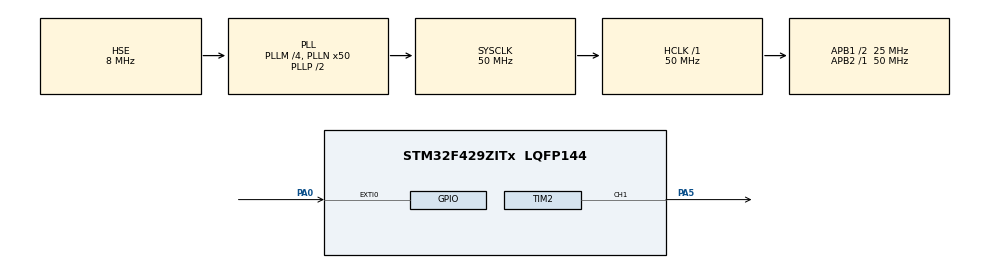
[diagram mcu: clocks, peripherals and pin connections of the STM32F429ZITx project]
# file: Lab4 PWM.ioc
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Mcu.Family=STM32F4
Mcu.Name=STM32F429ZITx
Mcu.Package=LQFP144
NVIC.EXTI0_IRQn=true\:0\:0\:false\:false\:true\:true\:true\:true
NVIC.PriorityGroup=NVIC_PRIORITYGROUP_4
PA0/WKUP.GPIO_ModeDefaultEXTI=GPIO_MODE_IT_RISING
PA0/WKUP.Signal=GPXTI0
PA13.Mode=Serial_Wire
PA13.Signal=SYS_JTMS-SWDIO
PA14.Mode=Serial_Wire
PA14.Signal=SYS_JTCK-SWCLK
PA5.Signal=S_TIM2_CH1_ETR
PH0/OSC_IN.Mode=HSE-External-Oscillator
PH0/OSC_IN.Signal=RCC_OSC_IN
PH1/OSC_OUT.Mode=HSE-External-Oscillator
PH1/OSC_OUT.Signal=RCC_OSC_OUT
ProjectManager.HeapSize=0x200
ProjectManager.StackSize=0x400
ProjectManager.TargetToolchain=STM32CubeIDE
RCC.48MHZClocksFreq_Value=25000000
RCC.AHBFreq_Value=50000000
RCC.APB1CLKDivider=RCC_HCLK_DIV2
RCC.APB1Freq_Value=25000000
RCC.APB1TimFreq_Value=50000000
RCC.APB2Freq_Value=50000000
RCC.APB2TimFreq_Value=50000000
RCC.CortexFreq_Value=50000000
RCC.HCLKFreq_Value=50000000
RCC.HSE_VALUE=8000000
RCC.HSI_VALUE=16000000
RCC.LSE_VALUE=32768
RCC.PLLM=4
RCC.PLLN=50
RCC.PLLSourceVirtual=RCC_PLLSOURCE_HSE
RCC.SYSCLKFreq_VALUE=50000000
RCC.SYSCLKSource=RCC_SYSCLKSOURCE_PLLCLK
RCC.VCOOutputFreq_Value=100000000
SH.S_TIM2_CH1_ETR.0=TIM2_CH1,PWM Generation1 CH1
TIM2.Channel-PWM\ Generation1\ CH1=TIM_CHANNEL_1
TIM2.CounterMode=TIM_COUNTERMODE_UP
TIM2.Period=0
TIM2.Prescaler=999
VP_TIM2_VS_ClockSourceINT.Mode=Internal
board=custom

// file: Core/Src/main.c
/* USER CODE BEGIN Header */
/**
  ******************************************************************************
  * @file           : main.c
  * @brief          : Main program body
  ******************************************************************************
  * @attention
  *
  * Copyright (c) 2024 STMicroelectronics.
  * All rights reserved.
  *
  * This software is licensed under terms that can be found in the LICENSE file
  * in the root directory of this software component.
  * If no LICENSE file comes with this software, it is provided AS-IS.
  *
  ******************************************************************************
  */
/* USER CODE END Header */
#include "main.h"

TIM_HandleTypeDef htim2;

/* USER CODE BEGIN PV */
int count_time = 0;
/* USER CODE END PV */

void SystemClock_Config(void);
static void MX_GPIO_Init(void);
static void MX_TIM2_Init(void);

int main(void)
{

  /* USER CODE BEGIN 1 */
	RCC->AHB1ENR |= 0x41;  // ВКЛ тактирование на LEDs (Подсистема RCC (Reset and Clock Control) включается для портов GPIOA и GPIOF)

	GPIOA->MODER &= ~0x03;  // ВКЛ кнопки (Порт GPIOA настраивается на общий режим вывода путем сброса двух младших битов регистра MODER)
  /* USER CODE END 1 */

  /* MCU Configuration--------------------------------------------------------*/

  /* Reset of all peripherals, Initializes the Flash interface and the Systick. */
  HAL_Init();

  /* Configure the system clock */
  SystemClock_Config();

  /* Initialize all configured peripherals */
  MX_GPIO_Init();
  MX_TIM2_Init();
  /* USER CODE BEGIN 2 */
  HAL_TIM_PWM_Start(&htim2, TIM_CHANNEL_1);  // запускаем генерацию Ш�?М-сигнала на таймере 2 канале 1
//  htim2.Instance->CCR2 = 99;  // Задается коэффициент заполнения Ш�??М-сигнала на TIM2, канал 2, равный 99 (значение в регистре влияет на яркость)
  htim2.Instance->CCR1 = 999;
  /* USER CODE END 2 */

  /* Infinite loop */
  /* USER CODE BEGIN WHILE */
  while (1)
  {
 	  if(count_time > 0)  // Если переменная count_time больше 0, коэффициент заполнения Ш�?М-сигнала обновляется в соответствии со значением count_time
	  {
//		  htim2.Instance->CCR2 = count_time / 50;
		  htim2.Instance->CCR1 = count_time / 10;  // обращаемся к регистру захвата-сравнения канала 1 таймера 2 (делитель влияет на плавность затухания)
	  }
	  else  // Если count_time не больше 0, коэффициент заполнения устанавливается в 0
	  {
		  htim2.Instance->CCR1 = 0;
//		  htim2.Instance->CCR2 = 0;
	  }
    /* USER CODE END WHILE */

  }
}

void SystemClock_Config(void)
{
  RCC_OscInitTypeDef RCC_OscInitStruct = {0};
  RCC_ClkInitTypeDef RCC_ClkInitStruct = {0};

  /** Configure the main internal regulator output voltage
  */
  __HAL_RCC_PWR_CLK_ENABLE();
  __HAL_PWR_VOLTAGESCALING_CONFIG(PWR_REGULATOR_VOLTAGE_SCALE3);

  /** Initializes the RCC Oscillators according to the specified parameters
  * in the RCC_OscInitTypeDef structure.
  */
  RCC_OscInitStruct.OscillatorType = RCC_OSCILLATORTYPE_HSE;
  RCC_OscInitStruct.HSEState = RCC_HSE_ON;
  RCC_OscInitStruct.PLL.PLLState = RCC_PLL_ON;
  RCC_OscInitStruct.PLL.PLLSource = RCC_PLLSOURCE_HSE;
  RCC_OscInitStruct.PLL.PLLM = 4;
  RCC_OscInitStruct.PLL.PLLN = 50;
  RCC_OscInitStruct.PLL.PLLP = RCC_PLLP_DIV2;
  RCC_OscInitStruct.PLL.PLLQ = 4;
  if (HAL_RCC_OscConfig(&RCC_OscInitStruct) != HAL_OK)
  {
    Error_Handler();
  }

  /** Initializes the CPU, AHB and APB buses clocks
  */
  RCC_ClkInitStruct.ClockType = RCC_CLOCKTYPE_HCLK|RCC_CLOCKTYPE_SYSCLK
                              |RCC_CLOCKTYPE_PCLK1|RCC_CLOCKTYPE_PCLK2;
  RCC_ClkInitStruct.SYSCLKSource = RCC_SYSCLKSOURCE_PLLCLK;
  RCC_ClkInitStruct.AHBCLKDivider = RCC_SYSCLK_DIV1;
  RCC_ClkInitStruct.APB1CLKDivider = RCC_HCLK_DIV2;
  RCC_ClkInitStruct.APB2CLKDivider = RCC_HCLK_DIV1;

  if (HAL_RCC_ClockConfig(&RCC_ClkInitStruct, FLASH_LATENCY_1) != HAL_OK)
  {
    Error_Handler();
  }
}

static void MX_TIM2_Init(void)
{

  TIM_ClockConfigTypeDef sClockSourceConfig = {0};
  TIM_MasterConfigTypeDef sMasterConfig = {0};
  TIM_OC_InitTypeDef sConfigOC = {0};

  htim2.Instance = TIM2;
  htim2.Init.Prescaler = 999;
  htim2.Init.CounterMode = TIM_COUNTERMODE_UP;
  htim2.Init.Period = 0;
  htim2.Init.ClockDivision = TIM_CLOCKDIVISION_DIV1;
  htim2.Init.AutoReloadPreload = TIM_AUTORELOAD_PRELOAD_DISABLE;
  if (HAL_TIM_Base_Init(&htim2) != HAL_OK)
  {
    Error_Handler();
  }
  sClockSourceConfig.ClockSource = TIM_CLOCKSOURCE_INTERNAL;
  if (HAL_TIM_ConfigClockSource(&htim2, &sClockSourceConfig) != HAL_OK)
  {
    Error_Handler();
  }
  if (HAL_TIM_PWM_Init(&htim2) != HAL_OK)
  {
    Error_Handler();
  }
  sMasterConfig.MasterOutputTrigger = TIM_TRGO_RESET;
  sMasterConfig.MasterSlaveMode = TIM_MASTERSLAVEMODE_DISABLE;
  if (HAL_TIMEx_MasterConfigSynchronization(&htim2, &sMasterConfig) != HAL_OK)
  {
    Error_Handler();
  }
  sConfigOC.OCMode = TIM_OCMODE_PWM1;
  sConfigOC.Pulse = 0;
  sConfigOC.OCPolarity = TIM_OCPOLARITY_HIGH;
  sConfigOC.OCFastMode = TIM_OCFAST_DISABLE;
  if (HAL_TIM_PWM_ConfigChannel(&htim2, &sConfigOC, TIM_CHANNEL_1) != HAL_OK)
  {
    Error_Handler();
  }
  HAL_TIM_MspPostInit(&htim2);

}

static void MX_GPIO_Init(void)
{
  GPIO_InitTypeDef GPIO_InitStruct = {0};

  /* GPIO Ports Clock Enable */
  __HAL_RCC_GPIOH_CLK_ENABLE();
  __HAL_RCC_GPIOA_CLK_ENABLE();

  /*Configure GPIO pin : PA0 */
  GPIO_InitStruct.Pin = GPIO_PIN_0;
  GPIO_InitStruct.Mode = GPIO_MODE_IT_RISING;
  GPIO_InitStruct.Pull = GPIO_NOPULL;
  HAL_GPIO_Init(GPIOA, &GPIO_InitStruct);

  /* EXTI interrupt init*/
  HAL_NVIC_SetPriority(EXTI0_IRQn, 0, 0);
  HAL_NVIC_EnableIRQ(EXTI0_IRQn);

}

void Error_Handler(void)
{
  __disable_irq();
  while (1)
  {
  }
}
